# HK32L0xx register map
Vendor: HKMicroChip Ltd.; Series: HK32L0xx; File version: 1.3
CPU: CM0 r0p0, little endian, no MPU, no FPU, 3 interrupt priority bits
Registers are 32-bit, read-write, reset 0x0 unless marked. A register's access mark holds for its fields unless they carry their own. Offsets are from the block's base; [hi:lo] are bit positions; {n}, {i} and the like mark numbered series.

## CRC
Base 0x40023000
0x00 DR reset 0xFFFFFFFF
  [31:0] DR — Data register
0x04 IDR
  [7:0] IDR — General purpose 8-bit data register
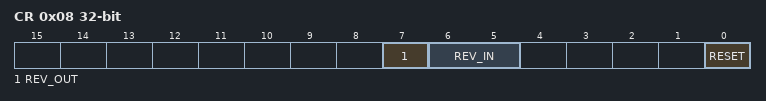
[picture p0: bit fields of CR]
0x08 CR
  [7] REV_OUT — Output data revert
  [6:5] REV_IN — Input data revert
  [0] RESET — Reset control
0x10 INIT reset 0xFFFFFFFF
  [31:0] CRC_INIT — CRC initiate value

## PWR
Base 0x40007000
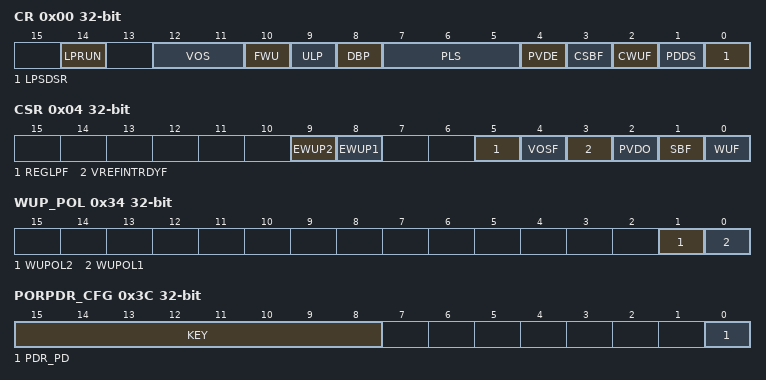
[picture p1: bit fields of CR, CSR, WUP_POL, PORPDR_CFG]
0x00 CR access per field
  [14] LPRUN rw — Low-power run mode
  [12:11] VOS rw — Voltage scaling range selection
  [10] FWU rw — Fast wakeup
  [9] ULP rw — Ultra-low-power mode
  [8] DBP rw — Disable backup write protection
  [7:5] PLS rw — PVD level selection
  [4] PVDE rw — Power voltage detector enable
  [3] CSBF rw — Clear standby flag
  [2] CWUF wo — Clear wakeup flag
  [1] PDDS rw — Power-down deepsleep
  [0] LPSDSR rw — Low-power deepsleep/Sleep/Low-power run
0x04 CSR access per field
  [9] EWUP2 rw — Enable WKUP pin2
  [8] EWUP1 rw — Enable WKUP pin1
  [5] REGLPF ro — Regulator low power flag
  [4] VOSF ro — Voltage scaling select flag
  [3] VREFINTRDYF ro — Internal voltage reference ready flag
  [2] PVDO ro — PVD output
  [1] SBF ro — Standby flag
  [0] WUF ro — Wakeup flag
0x34 WUP_POL
  [1] WUPOL2 — Wakeup pin2 polarity selection
  [0] WUPOL1 — Wakeup pin1 polarity selection
0x3C PORPDR_CFG access per field
  [15:8] KEY wo — Key to unlock PDR_PD
  [0] PDR_PD rw — PDR power-down in Standby/Shutdown mode

## SYSCFG
Base 0x40010000
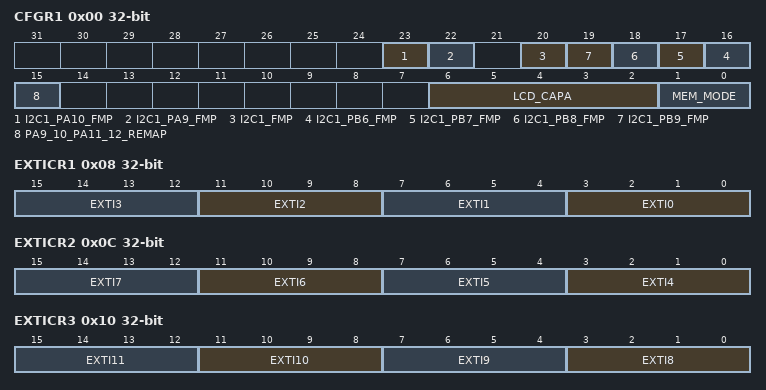
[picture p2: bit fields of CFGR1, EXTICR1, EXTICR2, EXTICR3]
0x00 CFGR1
  [23] I2C1_PA10_FMP — I2C1 Fast Mode Plus(FM+
  [22] I2C1_PA9_FMP — I2C1 Fast Mode Plus(FM+
  [20] I2C1_FMP — FM+ driving capability activation for I2C1
  [n+10] I2C1_PB{n}_FMP (n=6..9) — I2C1 Fast Mode Plus(FM+
  [15] PA9_10_PA11_12_REMAP — PA9/PA10 function remap to PA11/PA12
  [6:2] LCD_CAPA — LCD Capacitance
  [1:0] MEM_MODE — Memory mapping selection
0x08 EXTICR1
  [4n+3:4n] EXTI{n} (n=0..3) — EXTIy external interrupt source input selection
0x0C EXTICR2
  [4n-13:4n-16] EXTI{n} (n=4..7) — EXTIy external interrupt source input selection
0x10 EXTICR3
  [4n-29:4n-32] EXTI{n} (n=8..11) — EXTIy external interrupt source input selection
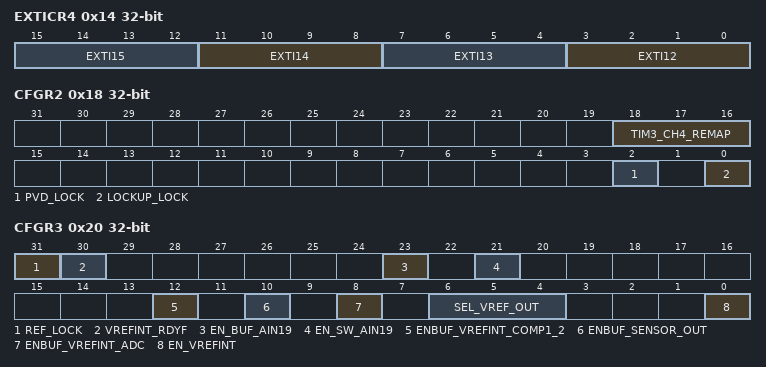
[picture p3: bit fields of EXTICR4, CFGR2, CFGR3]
0x14 EXTICR4
  [4n-45:4n-48] EXTI{n} (n=12..15) — EXTIy external interrupt source input selection
0x18 CFGR2
  [18:16] TIM3_CH4_REMAP — TIM3 channel4 remapping
  [2] PVD_LOCK — PVD lock enable bit
  [0] LOCKUP_LOCK — Cortex-M0 LOCKUP bit enable bit
0x20 CFGR3 access per field
  [31] REF_LOCK rw — SYSCFG_CFGR3 Register lock
  [30] VREFINT_RDYF ro — VREFINT read flag
  [23] EN_BUF_AIN19 rw — Enable buffer of ADC AIN19
  [21] EN_SW_AIN19 rw — Enable switch of ADC AIN19 weak in
  [12] ENBUF_VREFINT_COMP1_2 rw — VREFINT reference for COMP1 and COMP2 scaler enable bit
  [10] ENBUF_SENSOR_OUT rw — Enable switch of sensor out
  [8] ENBUF_VREFINT_ADC rw — VREFINT reference for ADC enable bit
  [6:4] SEL_VREF_OUT rw — VREFINT_ADC connection bit
  [0] EN_VREFINT rw — scaler for COMP1 and COMP2 enable bit

## GPIOA
Base 0x48000000
Same registers: GPIOB 0x48000400, GPIOC 0x48000800, GPIOD 0x48000C00, GPIOF 0x48001400
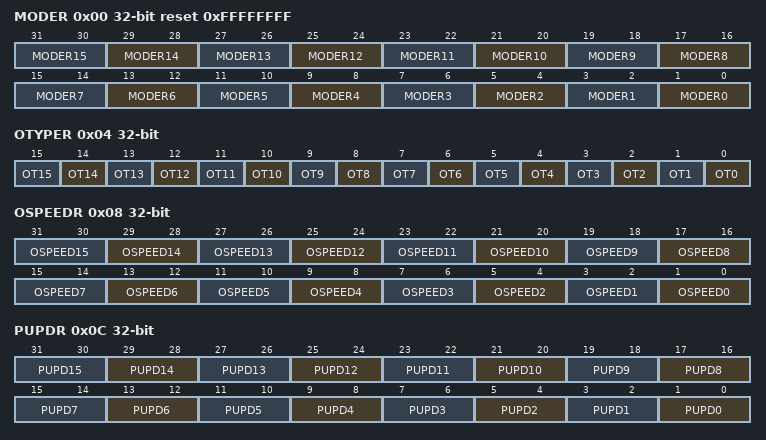
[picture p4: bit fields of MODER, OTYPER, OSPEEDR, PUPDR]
0x00 MODER reset 0xFFFFFFFF
  [2n+1:2n] MODER{n} (n=0..15) — Port x pin y mode bits
0x04 OTYPER
  [n] OT{n} (n=0..15) — Port x pin y output type bit
0x08 OSPEEDR
  [2n+1:2n] OSPEED{n} (n=0..15) — Port x pin y output speed bits
0x0C PUPDR
  [2n+1:2n] PUPD{n} (n=0..15) — Port x pin y pull -up/-down bits
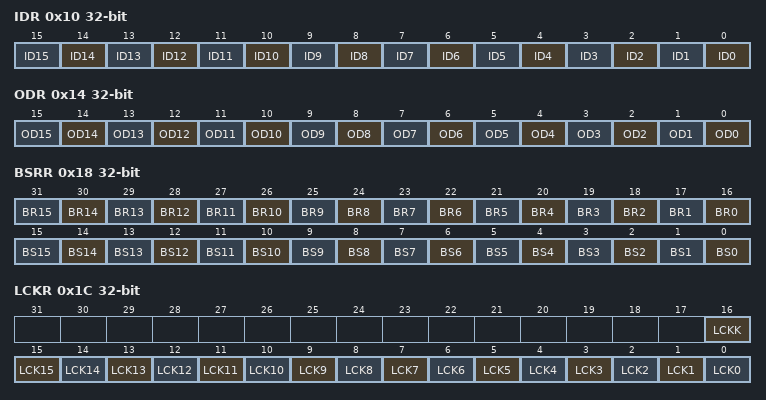
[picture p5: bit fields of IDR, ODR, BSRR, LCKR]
0x10 IDR ro
  [n] ID{n} (n=0..15) — Port x pin y input data bit
0x14 ODR
  [n] OD{n} (n=0..15) — Port x pin y output data bit
0x18 BSRR wo
  [n+16] BR{n} (n=0..15) — Port x pin y reset bit
  [n] BS{n} (n=0..15) — Port x pin y set bit
0x1C LCKR
  [16] LCKK — Lock key
  [n] LCK{n} (n=0..15) — Port x pin y lock bit
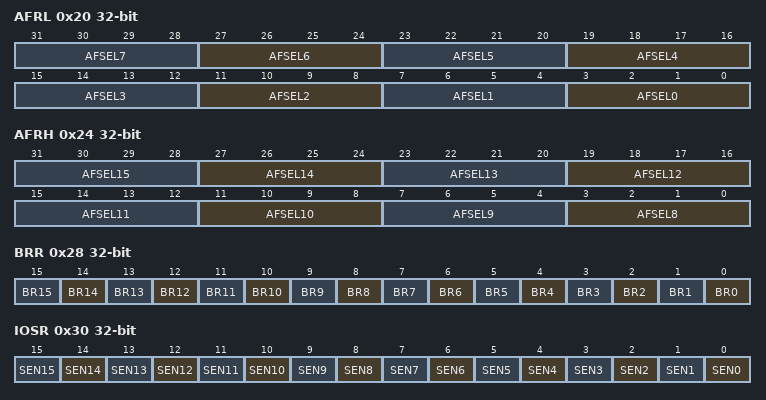
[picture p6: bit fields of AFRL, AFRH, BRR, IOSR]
0x20 AFRL
  [4n+3:4n] AFSEL{n} (n=0..7) — Alternate function selection low bits of port x pin y
0x24 AFRH
  [4n-29:4n-32] AFSEL{n} (n=8..15) — Alternate function selection high bits of port x pin y
0x28 BRR wo
  [n] BR{n} (n=0..15) — Port x pin y reset bit y
0x30 IOSR
  [n] SEN{n} (n=0..15) — Port x pin y Schmitt switch
